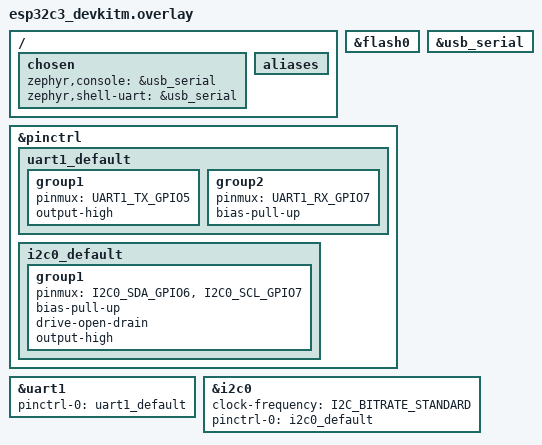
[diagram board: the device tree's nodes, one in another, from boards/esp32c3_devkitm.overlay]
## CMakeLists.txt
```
# SPDX-License-Identifier: Apache-2.0

cmake_minimum_required(VERSION 3.20.0)

find_package(Zephyr REQUIRED HINTS $ENV{ZEPHYR_BASE})
project(hello_world)

target_sources(app PRIVATE src/main.c src/uart_async.c)
```

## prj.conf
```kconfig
# nothing here
CONFIG_LOG=y
CONFIG_SHELL=y
CONFIG_I2C=y
CONFIG_REBOOT=y
CONFIG_I2C_SHELL=y
CONFIG_GPIO_SHELL=y
CONFIG_LOG_MODE_IMMEDIATE=y
CONFIG_WATCHDOG=y
CONFIG_WDT_LOG_LEVEL_INF=y
CONFIG_WDT_DISABLE_AT_BOOT=n
```

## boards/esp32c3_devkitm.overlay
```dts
/ {
    chosen {
        zephyr,console = &usb_serial;
        zephyr,shell-uart = &usb_serial;
    };

	aliases {
	};
};

&flash0 {
	status = "okay";
};

&usb_serial {
    status = "okay";
};

&pinctrl {
	uart1_default: uart1_default {
		group1 {
			pinmux = <UART1_TX_GPIO5>;
			output-high;
		};
		group2 {
			pinmux = <UART1_RX_GPIO7>;
			bias-pull-up;
		};
	};

	i2c0_default: i2c0_default {
		group1 {
			pinmux = <I2C0_SDA_GPIO6>, <I2C0_SCL_GPIO7>;
			bias-pull-up;
			drive-open-drain;
			output-high;
		};
	};

};

&uart1 {
    pinctrl-0 = <&uart1_default>;
    pinctrl-names = "default";
    status = "okay";
};


&i2c0 {
	status = "okay";
	clock-frequency = <I2C_BITRATE_STANDARD>;
	pinctrl-0 = <&i2c0_default>;
	pinctrl-names = "default";
};
```

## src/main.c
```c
/*
 * Copyright (c) 2012-2014 Wind River Systems, Inc.
 *
 * SPDX-License-Identifier: Apache-2.0
 */

#include <stdio.h>
#include <zephyr/device.h>
#include <zephyr/kernel.h>
#include <zephyr/sys/reboot.h>
#include <zephyr/shell/shell.h>
#include <zephyr/drivers/i2c.h>
#include <zephyr/drivers/gpio.h>
#include <zephyr/drivers/watchdog.h>
#include <stdlib.h>


#include <zephyr/logging/log.h>
LOG_MODULE_REGISTER(main, LOG_LEVEL_DBG);


static const struct device *const wdt = DEVICE_DT_GET(DT_ALIAS(watchdog0));
static int wdt_channel_id;
#define WDT_MAX_WINDOW  8000U
#define WDT_MIN_WINDOW  0U

static void wdt_callback(const struct device *wdt_dev, int channel_id)
{
	printk("watch dog channel %d, ready to reset...\n", channel_id);
	k_sleep(K_SECONDS(2));
}

int tc_watch_dog_init(void)
{
	int ret;

	if (!device_is_ready(wdt)) {
		printk("%s: device not ready.\n", wdt->name);
		return -ENODEV;
	}

	struct wdt_timeout_cfg wdt_config = {
		/* Reset SoC when watchdog timer expires. */
		.flags = WDT_FLAG_RESET_SOC,

		/* Expire watchdog after max window */
		.window.min = WDT_MIN_WINDOW,
		.window.max = WDT_MAX_WINDOW,
	};

	/* Set up watchdog callback. */
	wdt_config.callback = wdt_callback;

	wdt_channel_id = wdt_install_timeout(wdt, &wdt_config);
	if (wdt_channel_id == -ENOTSUP) {
		/* IWDG driver for STM32 doesn't support callback */
		printk("Callback support rejected, continuing anyway\n");
		wdt_config.callback = NULL;
		wdt_channel_id = wdt_install_timeout(wdt, &wdt_config);
	}
	if (wdt_channel_id < 0) {
		printk("Watchdog install error\n");
		return 0;
	}

	ret = wdt_setup(wdt, WDT_OPT_PAUSE_HALTED_BY_DBG);
	if (ret < 0) {
		printk("Watchdog setup error\n");
		return 0;
	}

	return 0;
}

void tc_watch_dog_feed()
{
	wdt_feed(wdt, wdt_channel_id);
}

void tc_watch_dog_set_enable(bool enable)
{
	int ret = -1;

	if(enable)
	{
		LOG_INF("watch dog enabled.");
		ret = wdt_setup(wdt, WDT_OPT_PAUSE_HALTED_BY_DBG);
		if (ret < 0) {
			LOG_ERR("Watchdog setup error, ret=%d\n", ret);
		}
	}else{
		LOG_INF("watch dog disabled.");
		ret = wdt_disable(wdt);
		if (ret < 0) {
			LOG_ERR("Watchdog setup error, ret=%d\n", ret);
		}
	}
}

int main(void)
{
	k_sleep(K_SECONDS(2));
	tc_watch_dog_init();
	
	LOG_INF("Hello World! %s\n", CONFIG_BOARD_TARGET);

	while(1)
	{
		//tc_watch_dog_feed();
		k_sleep(K_MSEC(1000));
	}

	return 0;
}

static uint8_t name[128];

int _example_modem_operation(const struct shell *sh, size_t argc, char *argv[])
{
	int operation = atoi(argv[1]);
	LOG_ERR("operation : %d", operation);
	if(1 == operation)
	{
/*
	[00:00:06.313,000] <err> main: operation : 1
	[00:00:06.316,000] <err> os: 
	[00:00:06.317,000] <err> os:  mcause: 7, Store/AMO access fault
	[00:00:06.319,000] <err> os:   mtval: 0
	[00:00:06.321,000] <err> os:      a0: 00000000    t0: 00000009
	[00:00:06.323,000] <err> os:      a1: 0000000e    t1: 40383a0e
	[00:00:06.325,000] <err> os:      a2: 00000000    t2: 00000009
	[00:00:06.327,000] <err> os:      a3: 3c0134c4    t3: 0000002a
	[00:00:06.330,000] <err> os:      a4: 00000001    t4: 0000002e
	[00:00:06.332,000] <err> os:      a5: 00000001    t5: 0000007f
	[00:00:06.334,000] <err> os:      a6: 00000068    t6: 00000010
	[00:00:06.337,000] <err> os:      a7: 0000006a
	[00:00:06.338,000] <err> os:      sp: 3fc8cc70
	[00:00:06.340,000] <err> os:      ra: 4200005e
	[00:00:06.342,000] <err> os:    mepc: 42000064
	[00:00:06.344,000] <err> os: mstatus: 00001880
	[00:00:06.346,000] <err> os: 
	[00:00:06.347,000] <err> os: call trace:
	[00:00:06.349,000] <err> os:       0: sp: 3fc8cc70 ra: 42000064
	[00:00:06.351,000] <err> os:       1: sp: 3fc8cc80 ra: 4200291c
	[00:00:06.354,000] <err> os:       2: sp: 3fc8ccc8 ra: 42000024
	[00:00:06.356,000] <err> os:       3: sp: 3fc8cd54 ra: 42003000
	[00:00:06.359,000] <err> os:       4: sp: 3fc8cd60 ra: 42002b3e
	[00:00:06.361,000] <err> os:       5: sp: 3fc8cd90 ra: 420036d4
	[00:00:06.364,000] <err> os:       6: sp: 3fc8cda0 ra: 42003f2a
	[00:00:06.366,000] <err> os:       7: sp: 3fc8ce40 ra: 42002000
	[00:00:06.369,000] <err> os: 
	[00:00:06.370,000] <err> os: >>> ZEPHYR FATAL ERROR 0: CPU exception on CPU 0
	[00:00:06.373,000] <err> os: Current thread: 0x3fc8f7b8 (shell_uart)
	[00:00:06.375,000] <err> os: Halting system
*/
		*((uint32_t *)NULL) = 1;
	}else if(2 == operation)
	{
		/* block */
		memset(name, 0, sizeof(name));
		LOG_WRN("memset to zero.");
	}else if(3 == operation)
	{
		tc_watch_dog_set_enable(true);
	}else if(4 == operation)
	{
		tc_watch_dog_set_enable(false);
	}

	
	return 0;
}

int _example_reboot(const struct shell *sh, size_t argc, char *argv[])
{
	LOG_WRN("REBOOT");
	k_sleep(K_SECONDS(2));
	sys_reboot(SYS_REBOOT_COLD);
	
	return 0;
}

SHELL_STATIC_SUBCMD_SET_CREATE(tc_modem_commands,
	SHELL_CMD(operation, NULL,
		"example for modem operation",
		_example_modem_operation),
	SHELL_CMD(reboot, NULL,
		"example reboot",
		_example_reboot),
	SHELL_SUBCMD_SET_END
);

SHELL_CMD_REGISTER(modem, &tc_modem_commands,
		   "example for uart-test", NULL);
```

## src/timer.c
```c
#include <zephyr/kernel.h>
#include <zephyr/device.h>
#include <zephyr/drivers/uart.h>
#include <zephyr/shell/shell.h>

#include <zephyr/logging/log.h>
LOG_MODULE_REGISTER(timer, LOG_LEVEL_DBG);

struct k_timer trip_upload_timer;

static void tc_uart_rx_thread(void *p1, void *p2, void *p3)
{

	while(1)
    {
        k_sleep(K_MSEC(1000));
    }
}

K_THREAD_DEFINE(uart_fifo, 4096, tc_uart_rx_thread, NULL, NULL, NULL, 99, 0, 1);

static void trip_timer_handler(struct k_timer *t_id)
{
	LOG_INF("callback");
}

int _example_timer_start(const struct shell *sh, size_t argc, char *argv[])
{
    static bool init = false;
    if(init == false)
    {
        init = true;
	    k_timer_init(&trip_upload_timer, trip_timer_handler, NULL);
        k_timer_start(&trip_upload_timer, K_NO_WAIT, K_SECONDS(5));

    }
	return 0;
}

int _example_timer_set(const struct shell *sh, size_t argc, char *argv[])
{
    
    
	return 0;
}

int _example_timer_stop(const struct shell *sh, size_t argc, char *argv[])
{
    k_timer_stop(&trip_upload_timer);

	return 0;
}

SHELL_STATIC_SUBCMD_SET_CREATE(tc_timer_commands,
SHELL_CMD(start, NULL,
		"example timer start",
		_example_timer_start),
        SHELL_CMD(set, NULL,
		"example timer set",
		_example_timer_set),
	SHELL_CMD(stop, NULL,
		"example timer stop",
		_example_timer_stop),
	SHELL_SUBCMD_SET_END
);

SHELL_CMD_REGISTER(timer, &tc_timer_commands,
		   "example for uart-test", NULL);
```

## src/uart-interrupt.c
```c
#include <zephyr/kernel.h>
#include <zephyr/device.h>
#include <zephyr/drivers/uart.h>
#include <zephyr/shell/shell.h>

#include <zephyr/logging/log.h>
LOG_MODULE_REGISTER(uart, LOG_LEVEL_DBG);

static uint8_t uart_rxbuffer[1024] = {0};
static struct ring_buf rx_rb;

static uint8_t uart_txbuffer[1024] = {0};
static struct ring_buf tx_rb;

const struct device *uart0 = DEVICE_DT_GET(DT_NODELABEL(uart1));

static void cb_handler_rx(const struct device *dev)
{
	uint8_t rxbuffer[32] = {0};

	int size = uart_fifo_read(dev, rxbuffer, sizeof(rxbuffer));
	if(size<=0)
	{
		LOG_ERR("failed to read uart: %d", size);
		return;
	}

	ring_buf_put(&rx_rb, rxbuffer, size);

	LOG_HEXDUMP_DBG(rxbuffer, size, "RX");
}

static void cb_handler_tx(const struct device *dev)
{
	uint8_t txbuffer[32] = {0};

	uint32_t cnt = ring_buf_get(&tx_rb, txbuffer, sizeof(txbuffer));

	if(cnt>0)
	{
		uart_fifo_fill(dev, txbuffer, cnt);
	}
	else if(uart_irq_tx_complete(dev))
	{
		uart_irq_tx_disable(dev);
	}
}

static void uart_cb_handler(const struct device *dev, void *user_data)
{
	if (uart_irq_update(dev) && uart_irq_is_pending(dev)) {

		if (uart_irq_rx_ready(dev)) {
			cb_handler_rx(dev);
		}

		if (uart_irq_tx_ready(dev)) {
			cb_handler_tx(dev);
		}
	}
}

static void tc_uart_rx_thread(void *p1, void *p2, void *p3)
{
	ring_buf_init(&rx_rb, sizeof(uart_rxbuffer), uart_rxbuffer);
	ring_buf_init(&tx_rb, sizeof(uart_txbuffer), uart_txbuffer);

	uart_irq_callback_user_data_set(uart0, uart_cb_handler, NULL);
    uart_irq_rx_enable(uart0);
	uart_irq_tx_disable(uart0);

	while(1)
    {
        k_sleep(K_MSEC(1000));
    }
}

static int tc_uart_tx(const struct device *uart, char *txbuffer, size_t size)
{
	ring_buf_put(&tx_rb, txbuffer, size);
	uart_irq_tx_enable(uart);

	return 0;
}

K_THREAD_DEFINE(uart_fifo, 4096, tc_uart_rx_thread, NULL, NULL, NULL, 99, 0, 1);

int _example_uart_tx(const struct shell *sh, size_t argc, char *argv[])
{
	if(argc != 2)
	{
		LOG_ERR("argument error!");
		return -EINVAL;
	}

	tc_uart_tx(uart0, argv[1], strlen(argv[1]));
	
	return 0;
}

int _example_uart_rx(const struct shell *sh, size_t argc, char *argv[])
{
	uint8_t rxbuffer[1024]={0};

	uint32_t cnt = ring_buf_get(&rx_rb, rxbuffer, sizeof(rxbuffer));

	LOG_INF("rx size : %d", cnt);

	LOG_HEXDUMP_DBG(rxbuffer, cnt, "RX");
	
	return 0;
}

SHELL_STATIC_SUBCMD_SET_CREATE(tc_uart_commands,
	SHELL_CMD(tx, NULL,
		"example uart tx",
		_example_uart_tx),
	SHELL_CMD(rx, NULL,
		"example uart rx",
		_example_uart_rx),
	SHELL_SUBCMD_SET_END
);

SHELL_CMD_REGISTER(uart, &tc_uart_commands,
		   "example for uart-test", NULL);
```

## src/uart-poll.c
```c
#include <zephyr/kernel.h>
#include <zephyr/device.h>
#include <zephyr/drivers/uart.h>
#include <zephyr/shell/shell.h>

#include <zephyr/logging/log.h>
LOG_MODULE_REGISTER(uart, LOG_LEVEL_DBG);

static uint8_t rxbuffer[1024] = {0};
static struct ring_buf rx_rb;

const struct device *uart0 = DEVICE_DT_GET(DT_NODELABEL(uart0));

static void tc_uart_rx_thread(void *p1, void *p2, void *p3)
{
	uint8_t ch = '\0';

	ring_buf_init(&rx_rb, sizeof(rxbuffer), rxbuffer);
    
	while(1)
    {
        while (!uart_poll_in(uart0, &ch)) {
		    ring_buf_put(&rx_rb, (uint8_t *)&ch, 1);
	    }
        k_sleep(K_MSEC(1));
    }
}

static int tc_uart_tx(const struct device *uart, char *txbuffer, size_t size)
{

	for (size_t i = 0; i < size; i++) {
		uart_poll_out(uart, txbuffer[i]);
	}

	return 0;
}

K_THREAD_DEFINE(uart_fifo, 4096, tc_uart_rx_thread, NULL, NULL, NULL, 99, 0, 1);

int _example_uart_tx(const struct shell *sh, size_t argc, char *argv[])
{
	if(argc != 2)
	{
		LOG_ERR("argument error!");
		return -EINVAL;
	}

	tc_uart_tx(uart0, argv[1], strlen(argv[1]));
	
	return 0;
}

int _example_uart_rx(const struct shell *sh, size_t argc, char *argv[])
{
	uint8_t rxbuffer[1024]={0};

	uint32_t cnt = ring_buf_get(&rx_rb, rxbuffer, sizeof(rxbuffer));

	LOG_INF("rx size : %d", cnt);

	LOG_HEXDUMP_DBG(rxbuffer, cnt, "RX");
	
	return 0;
}

SHELL_STATIC_SUBCMD_SET_CREATE(tc_uart_commands,
	SHELL_CMD(tx, NULL,
		"example uart tx",
		_example_uart_tx),
	SHELL_CMD(rx, NULL,
		"example uart rx",
		_example_uart_rx),
	SHELL_SUBCMD_SET_END
);

SHELL_CMD_REGISTER(uart, &tc_uart_commands,
		   "example for uart-test", NULL);
```

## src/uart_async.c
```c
/*
 * Copyright (c) 2020 Nordic Semiconductor ASA
 *
 * SPDX-License-Identifier: LicenseRef-Nordic-5-Clause
 */

#include <zephyr/kernel.h>
#include <zephyr/device.h>
#include <zephyr/devicetree.h>
#include <zephyr/logging/log.h>
#include <zephyr/drivers/uart.h>

LOG_MODULE_REGISTER(async, LOG_LEVEL_INF);

#define BUF_SIZE 512
static K_MEM_SLAB_DEFINE(uart_slab, BUF_SIZE, 3, 4);

static uint8_t uart_rxbuffer[2048] = {0};
static struct ring_buf uart_rx_rb;

uint8_t txbuffer[2048]="9012345678901234567890123456789012345678901234567890123456789012345678901234567890123456789012345678901234567890123456789012345678901234567890123456789012345678901234567890123456789012345678901234567890123456789012345678901234567890123456789012345678901234567890123456789012345678901234567890123456789012345678901234567890123456789012345678901234567890123456789012345678901234567890123456789012345678901234567890123456789012345678901234567890123456789012345678901234567890123456789012345678901234567890123456789012345678901234567890123456789012345678901234567890123456789012345678901234567890123456789012345678901234567890123456789012345678901234567890123456789012345678901234567890123456789012345678901234567890123456789012345678901234567890123456789012345678901234567890123456789012345678901234567890123456789012345678901234567890123456789012345678901234567890123456789012345678901234567890";

static void uart_async_callback(const struct device *dev, struct uart_event *evt, void *user_data)
{
	struct device *uart = user_data;
	int ret;

	switch (evt->type) {
	case UART_TX_DONE:
		LOG_DBG("Tx sent %d bytes", evt->data.tx.len);
		break;

	case UART_TX_ABORTED:
		LOG_ERR("Tx aborted");
		break;

	case UART_RX_RDY:
		LOG_INF("Received data %d bytes", evt->data.rx.len);
		LOG_HEXDUMP_DBG(evt->data.rx.buf + evt->data.rx.offset, evt->data.rx.len, "recv");
		
		if(ring_buf_put(&uart_rx_rb, evt->data.rx.buf + evt->data.rx.offset, evt->data.rx.len) != evt->data.rx.len)
		{
			LOG_WRN("ring buffer overflow.");
		}
		
		break;

	case UART_RX_BUF_REQUEST:
	{
		uint8_t *buf;

		ret = k_mem_slab_alloc(&uart_slab, (void **)&buf, K_NO_WAIT);
		__ASSERT(ret == 0, "Failed to allocate slab");

		ret = uart_rx_buf_rsp(uart, buf, BUF_SIZE);
		__ASSERT(ret == 0, "Failed to provide new buffer");
		break;
	}

	case UART_RX_BUF_RELEASED:
		k_mem_slab_free(&uart_slab, (void *)evt->data.rx_buf.buf);
		break;

	case UART_RX_DISABLED:
		break;

	case UART_RX_STOPPED:
		break;
	}
}
#define UART_ASYNC_TRANSMIT_LENGTH_MAX 64 /* DON'T CHANGE. */

static int uart_async_transmit(const struct device *dev, uint8_t *buffer, size_t size)
{
	int ret;
    size_t offset = 0;
    size_t length = 0;

	if(dev == NULL || buffer == NULL)
	{
		return -EINVAL;
	}

	for(;;)
	{
		if(size - offset >= UART_ASYNC_TRANSMIT_LENGTH_MAX)
		{
			length = UART_ASYNC_TRANSMIT_LENGTH_MAX;
		}else{
			length = size-offset;
		}

		if(length>0)
		{
			LOG_INF("tx length : %d", length);
			ret = uart_tx(dev, txbuffer+offset, length, 10000);
			LOG_DBG("L:%d -- error:%d\r\n", __LINE__, ret);

			offset += length;
			if(offset>=size)
			{
				break;
			}
		}else{
			break;
		}
	}

	return offset;
}

uint8_t templete[2048] = {0};

int uart_async_init(void)
{
	uint32_t index = 0;
	uint8_t *buf;
	const struct device *uart = DEVICE_DT_GET(DT_NODELABEL(uart0));

	ring_buf_init(&uart_rx_rb, sizeof(uart_rxbuffer), uart_rxbuffer);
	
	int ret = k_mem_slab_alloc(&uart_slab, (void **)&buf, K_NO_WAIT);
	if(ret)
	{
		LOG_DBG("L:%d -- error:%d\r\n", __LINE__, ret);
	}

	ret = uart_callback_set(uart, uart_async_callback, (void *)uart);
	if(ret)
	{
		LOG_DBG("L:%d -- error:%d\r\n", __LINE__, ret);
	}

	ret = uart_rx_enable(uart, buf, BUF_SIZE, 10000);
	if(ret)
	{
		LOG_DBG("L:%d -- error:%d\r\n", __LINE__, ret);
	}
	k_sleep(K_SECONDS(3));
	LOG_INF("ASYNC TX-RX TEST.");
	while(1)
	{
		LOG_INF("test index : %d", index++);
		uart_async_transmit(uart, txbuffer, strlen(txbuffer));
		uint32_t count = ring_buf_get(&uart_rx_rb, templete, sizeof(templete));

		LOG_INF("count : %d", count);

		if(count!=strlen(txbuffer))
		{
			LOG_ERR("size not the same.");
			break;
		}

		if(strcmp(templete, txbuffer) != 0)
		{
			LOG_ERR("content not the same.");

			LOG_HEXDUMP_DBG(txbuffer, strlen(txbuffer), "TX");

			LOG_HEXDUMP_DBG(templete, strlen(templete), "RX");

			break;
		}

		k_sleep(K_SECONDS(5));
	}
	return 0;
}
```
